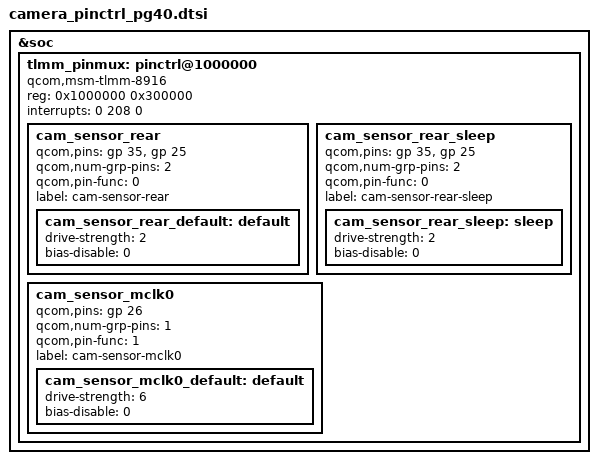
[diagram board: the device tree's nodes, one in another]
/* Copyright (c) 2013-2014, The Linux Foundation. All rights reserved.
 *
 * This program is free software; you can redistribute it and/or modify
 * it under the terms of the GNU General Public License version 2 and
 * only version 2 as published by the Free Software Foundation.
 *
 * This program is distributed in the hope that it will be useful,
 * but WITHOUT ANY WARRANTY; without even the implied warranty of
 * MERCHANTABILITY or FITNESS FOR A PARTICULAR PURPOSE.  See the
 * GNU General Public License for more details.
 */

&soc {
	tlmm_pinmux: pinctrl@1000000 {
		compatible = "qcom,msm-tlmm-8916";
		reg = <0x1000000 0x300000>;
		interrupts = <0 208 0>;

		/*****************************************/
		/*  pinctrl customize setting            */
		/*****************************************/
		cam_sensor_rear {
			/* RESET, STANDBY */
			qcom,pins =  <&gp 35>, <&gp 25>;
			qcom,num-grp-pins = <2>;
			qcom,pin-func = <0>;
			label = "cam-sensor-rear";
			/* active state */
			cam_sensor_rear_default: default {
				drive-strength = <2>; /* 2 MA */
				bias-disable = <0>; /* No PULL */
			};
		};

		cam_sensor_rear_sleep {
			/* RESET, STANDBY */
			qcom,pins =  <&gp 35>, <&gp 25>;
			qcom,num-grp-pins = <2>;
			qcom,pin-func = <0>;
			label = "cam-sensor-rear-sleep";
			/*suspended state */
			cam_sensor_rear_sleep: sleep {
				drive-strength = <2>; /* 2 MA */
				bias-disable = <0>; /*cft20160412 No PULL */
			};
		};

		cam_sensor_mclk0 {
			/* MCLK */
			qcom,pins = <&gp 26>;
			qcom,num-grp-pins = <1>;
			qcom,pin-func = <1>;
			label = "cam-sensor-mclk0";
			 /* active state */
			cam_sensor_mclk0_default: default {
				drive-strength = <6>; /*cft20150901_2    2 -> 6 MA */
				bias-disable = <0>; /* No PULL */
			};
		};

	};
};

